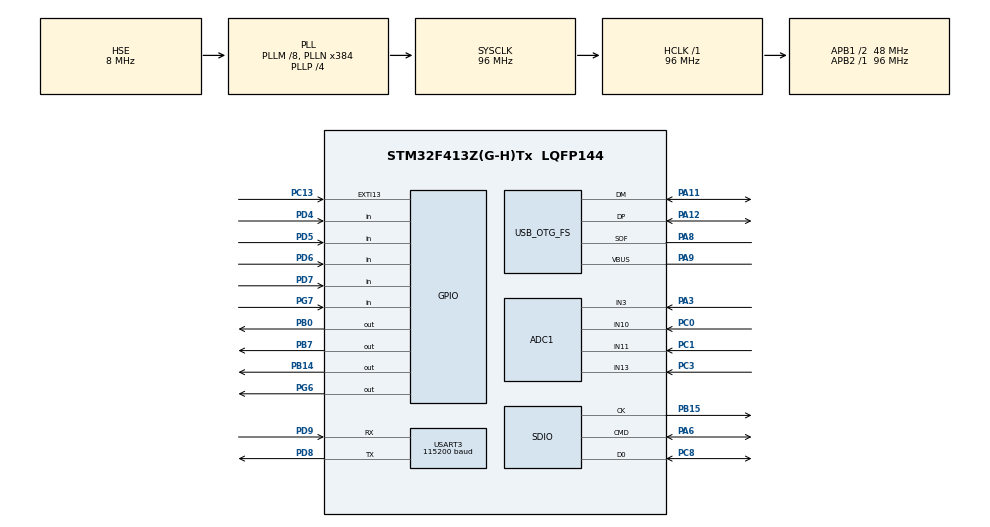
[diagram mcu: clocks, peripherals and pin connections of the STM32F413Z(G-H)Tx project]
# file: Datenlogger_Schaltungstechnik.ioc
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ADC1.Channel-4\#ChannelRegularConversion=ADC_CHANNEL_3
ADC1.Channel-5\#ChannelRegularConversion=ADC_CHANNEL_10
ADC1.Channel-6\#ChannelRegularConversion=ADC_CHANNEL_13
ADC1.Channel-7\#ChannelRegularConversion=ADC_CHANNEL_11
ADC1.ClockPrescaler=ADC_CLOCK_SYNC_PCLK_DIV8
ADC1.ContinuousConvMode=ENABLE
ADC1.DMAContinuousRequests=ENABLE
ADC1.EOCSelection=ADC_EOC_SEQ_CONV
ADC1.NbrOfConversion=4
ADC1.NbrOfConversionFlag=1
ADC1.Rank-4\#ChannelRegularConversion=1
ADC1.Rank-5\#ChannelRegularConversion=2
ADC1.Rank-6\#ChannelRegularConversion=3
ADC1.Rank-7\#ChannelRegularConversion=4
ADC1.SamplingTime-4\#ChannelRegularConversion=ADC_SAMPLETIME_56CYCLES
ADC1.SamplingTime-5\#ChannelRegularConversion=ADC_SAMPLETIME_56CYCLES
ADC1.SamplingTime-6\#ChannelRegularConversion=ADC_SAMPLETIME_56CYCLES
ADC1.SamplingTime-7\#ChannelRegularConversion=ADC_SAMPLETIME_56CYCLES
ADC1.ScanConvMode=ENABLE
ADC1.master=1
Dma.ADC1.0.Direction=DMA_PERIPH_TO_MEMORY
Dma.ADC1.0.FIFOMode=DMA_FIFOMODE_DISABLE
Dma.ADC1.0.Instance=DMA2_Stream0
Dma.ADC1.0.MemDataAlignment=DMA_MDATAALIGN_HALFWORD
Dma.ADC1.0.MemInc=DMA_MINC_ENABLE
Dma.ADC1.0.Mode=DMA_CIRCULAR
Dma.ADC1.0.PeriphDataAlignment=DMA_PDATAALIGN_HALFWORD
Dma.ADC1.0.PeriphInc=DMA_PINC_DISABLE
Dma.ADC1.0.Priority=DMA_PRIORITY_VERY_HIGH
Dma.Request0=ADC1
Mcu.Family=STM32F4
Mcu.Name=STM32F413Z(G-H)Tx
Mcu.Package=LQFP144
NVIC.DMA2_Stream0_IRQn=true\:0\:0\:false\:false\:true\:false\:true
NVIC.PriorityGroup=NVIC_PRIORITYGROUP_4
NVIC.TIM4_IRQn=true\:0\:0\:false\:false\:true\:true\:true
NVIC.USART3_IRQn=true\:0\:0\:false\:false\:true\:true\:true
PA10.GPIO_Mode=GPIO_MODE_AF_PP
PA10.GPIO_PuPd=GPIO_NOPULL
PA10.GPIO_Speed=GPIO_SPEED_FREQ_VERY_HIGH
PA10.Signal=USB_OTG_FS_ID
PA11.GPIO_Mode=GPIO_MODE_AF_PP
PA11.GPIO_PuPd=GPIO_NOPULL
PA11.GPIO_Speed=GPIO_SPEED_FREQ_VERY_HIGH
PA11.Mode=Device_Only
PA11.Signal=USB_OTG_FS_DM
PA12.GPIO_Mode=GPIO_MODE_AF_PP
PA12.GPIO_PuPd=GPIO_NOPULL
PA12.GPIO_Speed=GPIO_SPEED_FREQ_VERY_HIGH
PA12.Mode=Device_Only
PA12.Signal=USB_OTG_FS_DP
PA13.Mode=Trace_Asynchronous_SW
PA13.Signal=SYS_JTMS-SWDIO
PA14.Mode=Trace_Asynchronous_SW
PA14.Signal=SYS_JTCK-SWCLK
PA3.Signal=ADCx_IN3
PA5.Signal=SPI1_SCK
PA6.Mode=SD_1_bit
PA6.Signal=SDIO_CMD
PA8.GPIO_Mode=GPIO_MODE_AF_PP
PA8.GPIO_PuPd=GPIO_NOPULL
PA8.GPIO_Speed=GPIO_SPEED_FREQ_VERY_HIGH
PA8.Mode=Activate_SOF_FS
PA8.Signal=USB_OTG_FS_SOF
PA9.GPIO_Mode=GPIO_MODE_INPUT
PA9.GPIO_PuPd=GPIO_NOPULL
PA9.Mode=Activate_VBUS
PA9.Signal=USB_OTG_FS_VBUS
PB0.GPIO_ModeDefaultOutputPP=GPIO_MODE_OUTPUT_PP
PB0.GPIO_PuPd=GPIO_NOPULL
PB0.GPIO_Speed=GPIO_SPEED_FREQ_LOW
PB0.PinState=GPIO_PIN_RESET
PB0.Signal=GPIO_Output
PB14.GPIO_ModeDefaultOutputPP=GPIO_MODE_OUTPUT_PP
PB14.GPIO_PuPd=GPIO_NOPULL
PB14.GPIO_Speed=GPIO_SPEED_FREQ_LOW
PB14.PinState=GPIO_PIN_RESET
PB14.Signal=GPIO_Output
PB15.Mode=SD_1_bit
PB15.Signal=SDIO_CK
PB3.Mode=Trace_Asynchronous_SW
PB3.Signal=SYS_JTDO-SWO
PB7.GPIO_ModeDefaultOutputPP=GPIO_MODE_OUTPUT_PP
PB7.GPIO_PuPd=GPIO_NOPULL
PB7.GPIO_Speed=GPIO_SPEED_FREQ_LOW
PB7.PinState=GPIO_PIN_RESET
PB7.Signal=GPIO_Output
PC0.Signal=ADCx_IN10
PC1.Signal=ADCx_IN11
PC13.GPIO_ModeDefaultEXTI=GPIO_MODE_IT_RISING
PC13.GPIO_PuPd=GPIO_NOPULL
PC13.Signal=GPXTI13
PC14-OSC32_IN.Mode=LSE-External-Oscillator
PC14-OSC32_IN.Signal=RCC_OSC32_IN
PC15-OSC32_OUT.Mode=LSE-External-Oscillator
PC15-OSC32_OUT.Signal=RCC_OSC32_OUT
PC3.Signal=ADCx_IN13
PC8.Mode=SD_1_bit
PC8.Signal=SDIO_D0
PD4.GPIO_Mode=GPIO_MODE_INPUT
PD4.GPIO_PuPd=GPIO_PULLUP
PD4.Signal=GPIO_Input
PD5.GPIO_Mode=GPIO_MODE_INPUT
PD5.GPIO_PuPd=GPIO_PULLUP
PD5.Signal=GPIO_Input
PD6.GPIO_Mode=GPIO_MODE_INPUT
PD6.GPIO_PuPd=GPIO_PULLUP
PD6.Signal=GPIO_Input
PD7.GPIO_Mode=GPIO_MODE_INPUT
PD7.GPIO_PuPd=GPIO_PULLUP
PD7.Signal=GPIO_Input
PD8.GPIO_ModeDefaultPP=GPIO_MODE_AF_PP
PD8.GPIO_PuPd=GPIO_NOPULL
PD8.GPIO_Speed=GPIO_SPEED_FREQ_VERY_HIGH
PD8.Mode=Asynchronous
PD8.Signal=USART3_TX
PD9.GPIO_ModeDefaultPP=GPIO_MODE_AF_PP
PD9.GPIO_PuPd=GPIO_NOPULL
PD9.GPIO_Speed=GPIO_SPEED_FREQ_VERY_HIGH
PD9.Mode=Asynchronous
PD9.Signal=USART3_RX
PG6.GPIO_ModeDefaultOutputPP=GPIO_MODE_OUTPUT_PP
PG6.GPIO_PuPd=GPIO_NOPULL
PG6.GPIO_Speed=GPIO_SPEED_FREQ_LOW
PG6.PinState=GPIO_PIN_RESET
PG6.Signal=GPIO_Output
PG7.GPIO_Mode=GPIO_MODE_INPUT
PG7.GPIO_PuPd=GPIO_NOPULL
PG7.Signal=GPIO_Input
PH0\ -\ OSC_IN.Mode=HSE-External-Clock-Source
PH0\ -\ OSC_IN.Signal=RCC_OSC_IN
PH1\ -\ OSC_OUT.Mode=HSE-External-Clock-Source
PH1\ -\ OSC_OUT.Signal=RCC_OSC_OUT
ProjectManager.HeapSize=0x200
ProjectManager.StackSize=0x400
ProjectManager.TargetToolchain=STM32CubeIDE
RCC.48MHZClocksFreq_Value=24000000
RCC.AHBFreq_Value=96000000
RCC.APB1CLKDivider=RCC_HCLK_DIV2
RCC.APB1Freq_Value=48000000
RCC.APB1TimFreq_Value=96000000
RCC.APB2Freq_Value=96000000
RCC.APB2TimFreq_Value=96000000
RCC.CortexFreq_Value=96000000
RCC.HCLKFreq_Value=96000000
RCC.HSE_VALUE=8000000
RCC.HSI_VALUE=16000000
RCC.PLLM=8
RCC.PLLMUL=RCC_PLL_MUL9
RCC.PLLN=384
RCC.PLLP=RCC_PLLP_DIV4
RCC.PLLQ=8
RCC.PRESCALERUSB=RCC_USBCLKSOURCE_PLL_DIV1_5
RCC.SYSCLKFreq_VALUE=96000000
RCC.SYSCLKSource=RCC_SYSCLKSOURCE_PLLCLK
RCC.SYSCLKSourceVirtual=RCC_SYSCLKSOURCE_PLLCLK
RCC.USBFreq_Value=48000000
RCC.VCOOutputFreq_Value=384000000
SH.ADCx_IN10.0=ADC1_IN10,IN10
SH.ADCx_IN11.0=ADC1_IN11,IN11
SH.ADCx_IN13.0=ADC1_IN13,IN13
SH.ADCx_IN3.0=ADC1_IN3,IN3
TIM4.Period=100
TIM4.Prescaler=96
USART3.BaudRate=115200
USART3.VirtualMode=VM_ASYNC
USB_OTG_FS.VirtualMode=Device_Only
VP_TIM4_VS_ClockSourceINT.Mode=Internal
board=NUCLEO-F413ZH

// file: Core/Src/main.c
/* USER CODE BEGIN Header */
/**
  ******************************************************************************
  * @file           : main.c
  * @brief          : Main program body
  ******************************************************************************
  * @attention
  *
  * <h2><center>&copy; Copyright (c) 2020 STMicroelectronics.
  * All rights reserved.</center></h2>
  *
  * This software component is licensed by ST under BSD 3-Clause license,
  * the "License"; You may not use this file except in compliance with the
  * License. You may obtain a copy of the License at:
  *                        opensource.org/licenses/BSD-3-Clause
  *
  ******************************************************************************
  */
/* USER CODE END Header */

#include "main.h"
#include "adc.h"
#include "dma.h"
#include "sdio.h"
#include "tim.h"
#include "usart.h"
#include "usb_otg.h"
#include "gpio.h"

/* USER CODE BEGIN Includes */
#include "logger.h"
/* USER CODE END Includes */

void SystemClock_Config(void);

/* USER CODE BEGIN 0 */
uint32_t Cnt_Loop = 0;
uint32_t Cnt_tim4 = 0;
/* USER CODE END 0 */

int main(void)
{

  /* MCU Configuration--------------------------------------------------------*/

  /* Reset of all peripherals, Initializes the Flash interface and the Systick. */
  HAL_Init();

  /* Configure the system clock */
  SystemClock_Config();

  /* Initialize all configured peripherals */
  MX_GPIO_Init();
  MX_DMA_Init();
  MX_USART3_UART_Init();
  MX_ADC1_Init();
  MX_SDIO_SD_Init();
  MX_TIM4_Init();
  MX_USB_OTG_FS_PCD_Init();
  /* USER CODE BEGIN 2 */

  HAL_ADC_Start_DMA(&hadc1, (uint32_t*)adcSamples, 4);		// start ADC conversion with DMA
  HAL_UART_Receive_IT(&huart3, rxData, sizeof(rxData));		// sart Reciving Data from UART
  HAL_TIM_Base_Start_IT(&htim4);							// start Tim4 interrupt
  /* USER CODE END 2 */

  /* Infinite loop */
  /* USER CODE BEGIN WHILE */
  while (1)
  {

	  Cnt_Loop++;
    /* USER CODE END WHILE */

  }
}

void SystemClock_Config(void)
{
  RCC_OscInitTypeDef RCC_OscInitStruct = {0};
  RCC_ClkInitTypeDef RCC_ClkInitStruct = {0};
  RCC_PeriphCLKInitTypeDef PeriphClkInitStruct = {0};

  /** Configure the main internal regulator output voltage
  */
  __HAL_RCC_PWR_CLK_ENABLE();
  __HAL_PWR_VOLTAGESCALING_CONFIG(PWR_REGULATOR_VOLTAGE_SCALE1);
  /** Initializes the CPU, AHB and APB busses clocks
  */
  RCC_OscInitStruct.OscillatorType = RCC_OSCILLATORTYPE_HSE;
  RCC_OscInitStruct.HSEState = RCC_HSE_BYPASS;
  RCC_OscInitStruct.PLL.PLLState = RCC_PLL_ON;
  RCC_OscInitStruct.PLL.PLLSource = RCC_PLLSOURCE_HSE;
  RCC_OscInitStruct.PLL.PLLM = 8;
  RCC_OscInitStruct.PLL.PLLN = 384;
  RCC_OscInitStruct.PLL.PLLP = RCC_PLLP_DIV4;
  RCC_OscInitStruct.PLL.PLLQ = 8;
  RCC_OscInitStruct.PLL.PLLR = 2;
  if (HAL_RCC_OscConfig(&RCC_OscInitStruct) != HAL_OK)
  {
    Error_Handler();
  }
  /** Initializes the CPU, AHB and APB busses clocks
  */
  RCC_ClkInitStruct.ClockType = RCC_CLOCKTYPE_HCLK|RCC_CLOCKTYPE_SYSCLK
                              |RCC_CLOCKTYPE_PCLK1|RCC_CLOCKTYPE_PCLK2;
  RCC_ClkInitStruct.SYSCLKSource = RCC_SYSCLKSOURCE_PLLCLK;
  RCC_ClkInitStruct.AHBCLKDivider = RCC_SYSCLK_DIV1;
  RCC_ClkInitStruct.APB1CLKDivider = RCC_HCLK_DIV2;
  RCC_ClkInitStruct.APB2CLKDivider = RCC_HCLK_DIV1;

  if (HAL_RCC_ClockConfig(&RCC_ClkInitStruct, FLASH_LATENCY_3) != HAL_OK)
  {
    Error_Handler();
  }
  PeriphClkInitStruct.PeriphClockSelection = RCC_PERIPHCLK_SDIO|RCC_PERIPHCLK_CLK48;
  PeriphClkInitStruct.Clk48ClockSelection = RCC_CLK48CLKSOURCE_PLLQ;
  PeriphClkInitStruct.SdioClockSelection = RCC_SDIOCLKSOURCE_CLK48;
  if (HAL_RCCEx_PeriphCLKConfig(&PeriphClkInitStruct) != HAL_OK)
  {
    Error_Handler();
  }
}

/* USER CODE BEGIN 4 */
void HAL_TIM_PeriodElapsedCallback(TIM_HandleTypeDef *htim) {
	adc_100us();		// transform raw adc values
	TrigHandler();		// run Trigger FSM
	DataHandler();		// run Data handler FSM
	Cnt_tim4++;			// counter to monitor Timer Interrupt
}

/* USER CODE END 4 */

void Error_Handler(void)
{
}

/************************ (C) COPYRIGHT STMicroelectronics *****END OF FILE****/
